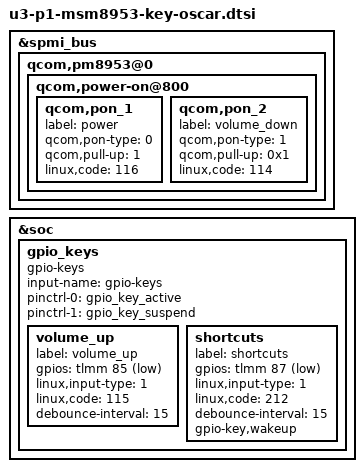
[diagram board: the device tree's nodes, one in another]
&spmi_bus {
	qcom,pm8953@0 {
		qcom,power-on@800 {
			/* Power */
			qcom,pon_1 {
				label = "power";
				qcom,pon-type = <0>;
				qcom,pull-up = <1>;
				linux,code = <116>;
			};

			/* Volume Down */
			qcom,pon_2 {
				label = "volume_down";
				qcom,pon-type = <1>;
				qcom,pull-up = <1>;
				linux,code = <114>;
				qcom,pull-up = <0x1>;
			};
		};
	};
};

&soc {
	/delete-node/ gpio_keys;

	gpio_keys {
		compatible = "gpio-keys";
		input-name = "gpio-keys";
		pinctrl-names = "tlmm_gpio_key_active","tlmm_gpio_key_suspend";
		pinctrl-0 = <&gpio_key_active>;
		pinctrl-1 = <&gpio_key_suspend>;

		/* Volume Up */
		volume_up {
			label = "volume_up";
			gpios = <&tlmm 85 0x1>;
			linux,input-type = <1>;
			linux,code = <115>;
			debounce-interval = <15>;
		};

		/* Shortcuts */
		shortcuts {
			label = "shortcuts";
			gpios = <&tlmm 87 0x1>;
			linux,input-type = <1>;
			linux,code = <212>;
			debounce-interval = <15>;
			gpio-key,wakeup;
		};
	};
};
